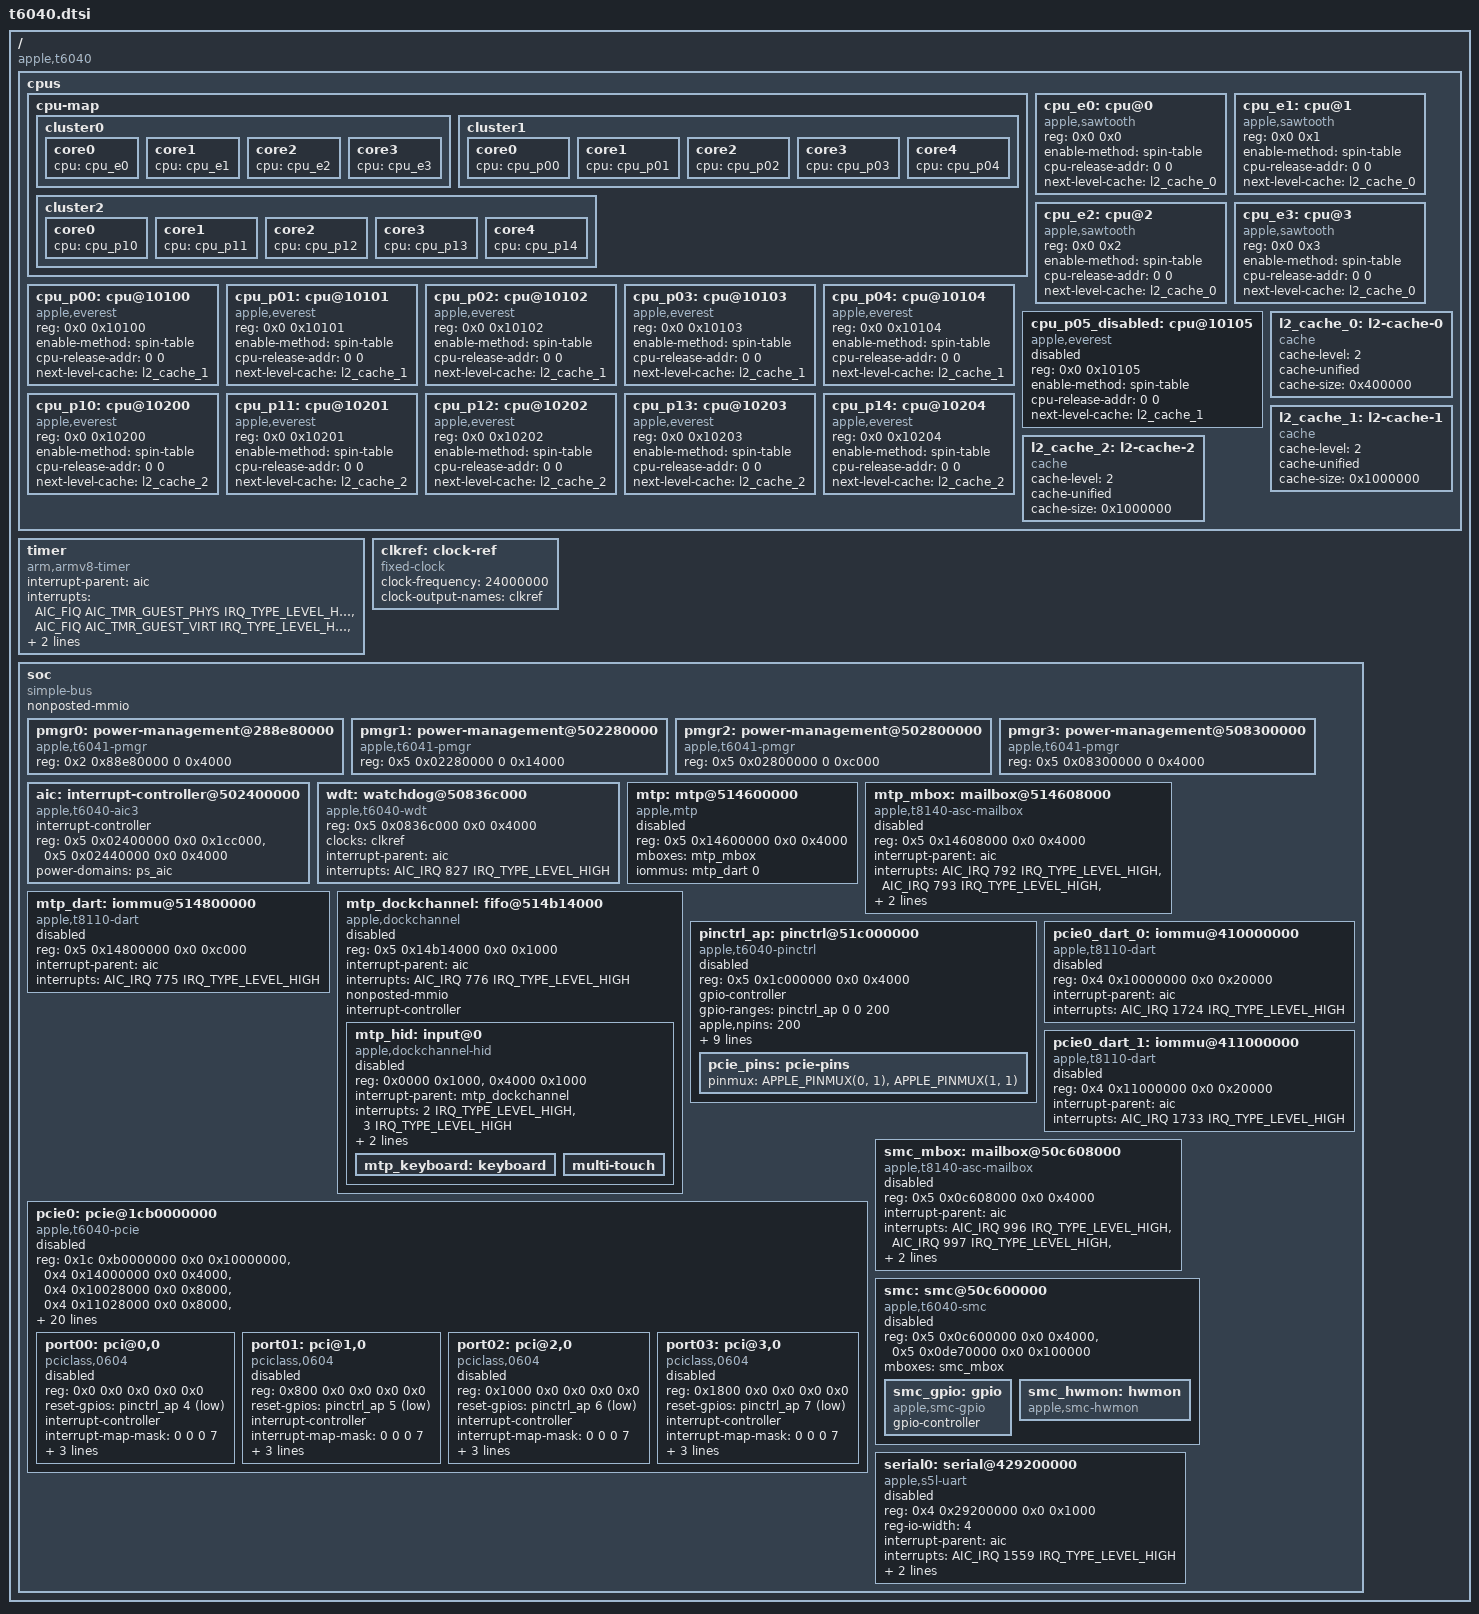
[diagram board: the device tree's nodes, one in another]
// SPDX-License-Identifier: GPL-2.0+ OR MIT
/*
 * Apple T6040 "M4 Pro" SoC
 *
 * The M4-generation Pro die: fills the gap between t8132 (M4) and t6050
 * (M5 Pro/Max). M4-generation IP (apple,sawtooth E / apple,everest P cores,
 * t8122-aic3) in a Pro-die multi-cluster layout (4E + 5P + 5P).
 *
 * All reg/irq values verified against the live j614s ADT (2026-07-10); see
 * m1n1 .plans/2026-07-10-t6040-kboot-fdt-plan.md and dts/README.md.
 *
 * Copyright The Asahi Linux Contributors
 */

#include <dt-bindings/gpio/gpio.h>
#include <dt-bindings/interrupt-controller/apple-aic.h>
#include <dt-bindings/interrupt-controller/irq.h>
#include <dt-bindings/pinctrl/apple.h>

/ {
	compatible = "apple,t6040", "apple,arm-platform";

	#address-cells = <2>;
	#size-cells = <2>;

	cpus {
		#address-cells = <2>;
		#size-cells = <0>;

		cpu-map {
			cluster0 {
				core0 {
					cpu = <&cpu_e0>;
				};
				core1 {
					cpu = <&cpu_e1>;
				};
				core2 {
					cpu = <&cpu_e2>;
				};
				core3 {
					cpu = <&cpu_e3>;
				};
			};

			cluster1 {
				core0 {
					cpu = <&cpu_p00>;
				};
				core1 {
					cpu = <&cpu_p01>;
				};
				core2 {
					cpu = <&cpu_p02>;
				};
				core3 {
					cpu = <&cpu_p03>;
				};
				core4 {
					cpu = <&cpu_p04>;
				};
			};

			cluster2 {
				core0 {
					cpu = <&cpu_p10>;
				};
				core1 {
					cpu = <&cpu_p11>;
				};
				core2 {
					cpu = <&cpu_p12>;
				};
				core3 {
					cpu = <&cpu_p13>;
				};
				core4 {
					cpu = <&cpu_p14>;
				};
			};
		};

		cpu_e0: cpu@0 {
			compatible = "apple,sawtooth";
			device_type = "cpu";
			reg = <0x0 0x0>;
			enable-method = "spin-table";
			cpu-release-addr = <0 0>;
			next-level-cache = <&l2_cache_0>;
		};

		cpu_e1: cpu@1 {
			compatible = "apple,sawtooth";
			device_type = "cpu";
			reg = <0x0 0x1>;
			enable-method = "spin-table";
			cpu-release-addr = <0 0>;
			next-level-cache = <&l2_cache_0>;
		};

		cpu_e2: cpu@2 {
			compatible = "apple,sawtooth";
			device_type = "cpu";
			reg = <0x0 0x2>;
			enable-method = "spin-table";
			cpu-release-addr = <0 0>;
			next-level-cache = <&l2_cache_0>;
		};

		cpu_e3: cpu@3 {
			compatible = "apple,sawtooth";
			device_type = "cpu";
			reg = <0x0 0x3>;
			enable-method = "spin-table";
			cpu-release-addr = <0 0>;
			next-level-cache = <&l2_cache_0>;
		};

		cpu_p00: cpu@10100 {
			compatible = "apple,everest";
			device_type = "cpu";
			reg = <0x0 0x10100>;
			enable-method = "spin-table";
			cpu-release-addr = <0 0>;
			next-level-cache = <&l2_cache_1>;
		};

		cpu_p01: cpu@10101 {
			compatible = "apple,everest";
			device_type = "cpu";
			reg = <0x0 0x10101>;
			enable-method = "spin-table";
			cpu-release-addr = <0 0>;
			next-level-cache = <&l2_cache_1>;
		};

		cpu_p02: cpu@10102 {
			compatible = "apple,everest";
			device_type = "cpu";
			reg = <0x0 0x10102>;
			enable-method = "spin-table";
			cpu-release-addr = <0 0>;
			next-level-cache = <&l2_cache_1>;
		};

		cpu_p03: cpu@10103 {
			compatible = "apple,everest";
			device_type = "cpu";
			reg = <0x0 0x10103>;
			enable-method = "spin-table";
			cpu-release-addr = <0 0>;
			next-level-cache = <&l2_cache_1>;
		};

		cpu_p04: cpu@10104 {
			compatible = "apple,everest";
			device_type = "cpu";
			reg = <0x0 0x10104>;
			enable-method = "spin-table";
			cpu-release-addr = <0 0>;
			next-level-cache = <&l2_cache_1>;
		};

		/*
		 * t6040 is a chopped t6041 (M4 Max): the full P-cluster0 has 6 cores
		 * (MPIDR 0x10100..0x10105) but the 6th is fused off here. m1n1 still
		 * enumerates it as smp_id 9 (Apple's non-contiguous ADT numbering) and
		 * expects a DT cpu node at that positional slot to prune — dt_set_cpus
		 * uses a positional counter, so without this the P-cl1 nodes shift by one
		 * and fail MPIDR matching. NOT in cpu-map (m1n1 nops the node but does not
		 * clean cpu-map references), so it never reaches Linux.
		 */
		cpu_p05_disabled: cpu@10105 {
			compatible = "apple,everest";
			device_type = "cpu";
			reg = <0x0 0x10105>;
			enable-method = "spin-table";
			cpu-release-addr = <0 0>;
			next-level-cache = <&l2_cache_1>;
			status = "disabled";
		};

		cpu_p10: cpu@10200 {
			compatible = "apple,everest";
			device_type = "cpu";
			reg = <0x0 0x10200>;
			enable-method = "spin-table";
			cpu-release-addr = <0 0>;
			next-level-cache = <&l2_cache_2>;
		};

		cpu_p11: cpu@10201 {
			compatible = "apple,everest";
			device_type = "cpu";
			reg = <0x0 0x10201>;
			enable-method = "spin-table";
			cpu-release-addr = <0 0>;
			next-level-cache = <&l2_cache_2>;
		};

		cpu_p12: cpu@10202 {
			compatible = "apple,everest";
			device_type = "cpu";
			reg = <0x0 0x10202>;
			enable-method = "spin-table";
			cpu-release-addr = <0 0>;
			next-level-cache = <&l2_cache_2>;
		};

		cpu_p13: cpu@10203 {
			compatible = "apple,everest";
			device_type = "cpu";
			reg = <0x0 0x10203>;
			enable-method = "spin-table";
			cpu-release-addr = <0 0>;
			next-level-cache = <&l2_cache_2>;
		};

		cpu_p14: cpu@10204 {
			compatible = "apple,everest";
			device_type = "cpu";
			reg = <0x0 0x10204>;
			enable-method = "spin-table";
			cpu-release-addr = <0 0>;
			next-level-cache = <&l2_cache_2>;
		};

		l2_cache_0: l2-cache-0 {
			compatible = "cache";
			cache-level = <2>;
			cache-unified;
			cache-size = <0x400000>;
		};

		l2_cache_1: l2-cache-1 {
			compatible = "cache";
			cache-level = <2>;
			cache-unified;
			cache-size = <0x1000000>;
		};

		l2_cache_2: l2-cache-2 {
			compatible = "cache";
			cache-level = <2>;
			cache-unified;
			cache-size = <0x1000000>;
		};
	};

	timer {
		compatible = "arm,armv8-timer";
		interrupt-parent = <&aic>;
		interrupt-names = "phys", "virt", "hyp-phys", "hyp-virt";
		interrupts = <AIC_FIQ AIC_TMR_GUEST_PHYS IRQ_TYPE_LEVEL_HIGH>,
			     <AIC_FIQ AIC_TMR_GUEST_VIRT IRQ_TYPE_LEVEL_HIGH>,
			     <AIC_FIQ AIC_TMR_HV_PHYS IRQ_TYPE_LEVEL_HIGH>,
			     <AIC_FIQ AIC_TMR_HV_VIRT IRQ_TYPE_LEVEL_HIGH>;
	};

	clkref: clock-ref {
		compatible = "fixed-clock";
		#clock-cells = <0>;
		clock-frequency = <24000000>;
		clock-output-names = "clkref";
	};

	soc: soc {
		compatible = "simple-bus";
		#address-cells = <2>;
		#size-cells = <2>;

		ranges;
		nonposted-mmio;

		/* pmgr nodes; child power-controllers added in t6040-pmgr.dtsi */
		pmgr0: power-management@288e80000 {
			compatible = "apple,t6041-pmgr", "apple,t8103-pmgr", "syscon", "simple-mfd";
			#address-cells = <1>;
			#size-cells = <1>;
			reg = <0x2 0x88e80000 0 0x4000>;
		};

		pmgr1: power-management@502280000 {
			compatible = "apple,t6041-pmgr", "apple,t8103-pmgr", "syscon", "simple-mfd";
			#address-cells = <1>;
			#size-cells = <1>;
			reg = <0x5 0x02280000 0 0x14000>;
		};

		pmgr2: power-management@502800000 {
			compatible = "apple,t6041-pmgr", "apple,t8103-pmgr", "syscon", "simple-mfd";
			#address-cells = <1>;
			#size-cells = <1>;
			reg = <0x5 0x02800000 0 0xc000>;
		};

		pmgr3: power-management@508300000 {
			compatible = "apple,t6041-pmgr", "apple,t8103-pmgr", "syscon", "simple-mfd";
			#address-cells = <1>;
			#size-cells = <1>;
			reg = <0x5 0x08300000 0 0x4000>;
		};

		aic: interrupt-controller@502400000 {
			compatible = "apple,t6040-aic3", "apple,t8122-aic3";
			#interrupt-cells = <3>;
			interrupt-controller;

			/*
			 * reg[0]: Main MMIO range
			 * reg[1]: CPU Event/IACK register page (Base + aic-iack-offset 0x40000)
			 */
			reg = <0x5 0x02400000 0x0 0x1cc000>,
			      <0x5 0x02440000 0x0 0x4000>;
			reg-names = "core", "event";
			power-domains = <&ps_aic>;
		};

		wdt: watchdog@50836c000 {
			compatible = "apple,t6040-wdt", "apple,t8103-wdt";
			reg = <0x5 0x0836c000 0x0 0x4000>;
			clocks = <&clkref>;
			interrupt-parent = <&aic>;
			interrupts = <AIC_IRQ 827 IRQ_TYPE_LEVEL_HIGH>;
		};

		/*
		 * MTP carries the internal keyboard and trackpad over DockChannel.
		 * All addresses and IRQs below are from the J614s ADT. Keep the
		 * complete path disabled in the SoC description; the board-level
		 * bring-up DT enables it as one deliberately gated unit.
		 */
		mtp: mtp@514600000 {
			compatible = "apple,mtp", "apple,rtk-helper-asc4";
			reg = <0x5 0x14600000 0x0 0x4000>;
			reg-names = "asc";
			mboxes = <&mtp_mbox>;
			iommus = <&mtp_dart 0>;
			#helper-cells = <0>;
			status = "disabled";
		};

		mtp_mbox: mailbox@514608000 {
			compatible = "apple,t8140-asc-mailbox", "apple,asc-mailbox-v4";
			reg = <0x5 0x14608000 0x0 0x4000>;
			interrupt-parent = <&aic>;
			/*
			 * The J614s ADT lists these as [793, 792, 795, 794],
			 * with not-empty first in each pair. Linux's binding is
			 * semantic empty/not-empty order, so map the physical lines
			 * to [792, 793, 794, 795]. Exact J614s testing found that
			 * keeping raw ADT order loses the MTP hello interrupt.
			 */
			interrupts = <AIC_IRQ 792 IRQ_TYPE_LEVEL_HIGH>,
				     <AIC_IRQ 793 IRQ_TYPE_LEVEL_HIGH>,
				     <AIC_IRQ 794 IRQ_TYPE_LEVEL_HIGH>,
				     <AIC_IRQ 795 IRQ_TYPE_LEVEL_HIGH>;
			interrupt-names = "send-empty", "send-not-empty",
					  "recv-empty", "recv-not-empty";
			#mbox-cells = <0>;
			status = "disabled";
		};

		mtp_dart: iommu@514800000 {
			compatible = "apple,t8110-dart";
			reg = <0x5 0x14800000 0x0 0xc000>;
			interrupt-parent = <&aic>;
			interrupts = <AIC_IRQ 775 IRQ_TYPE_LEVEL_HIGH>;
			#iommu-cells = <1>;
			status = "disabled";
		};

		mtp_dockchannel: fifo@514b14000 {
			compatible = "apple,dockchannel";
			reg = <0x5 0x14b14000 0x0 0x1000>;
			reg-names = "irq";
			interrupt-parent = <&aic>;
			interrupts = <AIC_IRQ 776 IRQ_TYPE_LEVEL_HIGH>;
			ranges = <0x0 0x5 0x14b30000 0x8000>;
			nonposted-mmio;
			#address-cells = <1>;
			#size-cells = <1>;
			interrupt-controller;
			#interrupt-cells = <2>;
			status = "disabled";

			mtp_hid: input@0 {
				compatible = "apple,dockchannel-hid";
				reg = <0x0000 0x1000>,
				      <0x4000 0x1000>;
				reg-names = "config", "data";
				interrupt-parent = <&mtp_dockchannel>;
				interrupts = <2 IRQ_TYPE_LEVEL_HIGH>,
					     <3 IRQ_TYPE_LEVEL_HIGH>;
				interrupt-names = "tx", "rx";
				apple,fifo-size = <0x800>;
				apple,helper-cpu = <&mtp>;
				status = "disabled";

				mtp_keyboard: keyboard {
				};

				multi-touch {
				};
			};
		};

		/*
		 * ADT /arm-io/gpio0: 200 pins and seven AIC interrupt groups.
		 * PCIe CLKREQ for populated ports 0/1 is GPIO 0/1, function 1.
		 * Keep the controller disabled until a board variant enables a
		 * PCIe endpoint path.
		 */
		pinctrl_ap: pinctrl@51c000000 {
			compatible = "apple,t6040-pinctrl", "apple,t8122-pinctrl",
				     "apple,t8103-pinctrl";
			reg = <0x5 0x1c000000 0x0 0x4000>;

			gpio-controller;
			#gpio-cells = <2>;
			gpio-ranges = <&pinctrl_ap 0 0 200>;
			apple,npins = <200>;

			interrupt-controller;
			#interrupt-cells = <2>;
			interrupt-parent = <&aic>;
			interrupts = <AIC_IRQ 478 IRQ_TYPE_LEVEL_HIGH>,
				     <AIC_IRQ 479 IRQ_TYPE_LEVEL_HIGH>,
				     <AIC_IRQ 480 IRQ_TYPE_LEVEL_HIGH>,
				     <AIC_IRQ 481 IRQ_TYPE_LEVEL_HIGH>,
				     <AIC_IRQ 482 IRQ_TYPE_LEVEL_HIGH>,
				     <AIC_IRQ 483 IRQ_TYPE_LEVEL_HIGH>,
				     <AIC_IRQ 484 IRQ_TYPE_LEVEL_HIGH>;
			status = "disabled";

			pcie_pins: pcie-pins {
				pinmux = <APPLE_PINMUX(0, 1)>,
					 <APPLE_PINMUX(1, 1)>;
			};
		};

		pcie0_dart_0: iommu@410000000 {
			compatible = "apple,t8110-dart";
			reg = <0x4 0x10000000 0x0 0x20000>;
			interrupt-parent = <&aic>;
			interrupts = <AIC_IRQ 1724 IRQ_TYPE_LEVEL_HIGH>;
			#iommu-cells = <1>;
			status = "disabled";
		};

		pcie0_dart_1: iommu@411000000 {
			compatible = "apple,t8110-dart";
			reg = <0x4 0x11000000 0x0 0x20000>;
			interrupt-parent = <&aic>;
			interrupts = <AIC_IRQ 1733 IRQ_TYPE_LEVEL_HIGH>;
			#iommu-cells = <1>;
			status = "disabled";
		};

		/*
		 * T6040 uses the T602x Linux-visible port layout. m1n1 owns
		 * shared PHY/clock initialization and leaves the complete ADT
		 * power-gate set active. Do not approximate the T6040
		 * APCIE_SYS_GP + APCIE_PHY_SW hierarchy with the binding's
		 * single power-domains entry.
		 */
		pcie0: pcie@1cb0000000 {
			compatible = "apple,t6040-pcie", "apple,t6020-pcie";
			device_type = "pci";

			reg = <0x1c 0xb0000000 0x0 0x10000000>,
			      <0x4 0x14000000 0x0 0x4000>,
			      <0x4 0x10028000 0x0 0x8000>,
			      <0x4 0x11028000 0x0 0x8000>,
			      <0x4 0x12028000 0x0 0x8000>,
			      <0x4 0x13028000 0x0 0x8000>,
			      <0x4 0x17020000 0x0 0x4000>,
			      <0x4 0x17024000 0x0 0x4000>,
			      <0x4 0x17028000 0x0 0x4000>,
			      <0x4 0x1702c000 0x0 0x4000>;
			reg-names = "config", "rc",
				    "port0", "port1", "port2", "port3",
				    "phy0", "phy1", "phy2", "phy3";

			interrupt-parent = <&aic>;
			interrupts = <AIC_IRQ 1723 IRQ_TYPE_LEVEL_HIGH>,
				     <AIC_IRQ 1732 IRQ_TYPE_LEVEL_HIGH>,
				     <AIC_IRQ 1741 IRQ_TYPE_LEVEL_HIGH>,
				     <AIC_IRQ 1750 IRQ_TYPE_LEVEL_HIGH>;

			msi-controller;
			msi-parent = <&pcie0>;
			msi-ranges = <&aic AIC_IRQ 2071 IRQ_TYPE_EDGE_RISING 32>;

			iommu-map = <0x100 &pcie0_dart_0 1 1>,
				    <0x200 &pcie0_dart_1 1 1>;
			iommu-map-mask = <0xff00>;

			bus-range = <0 8>;
			#address-cells = <3>;
			#size-cells = <2>;
			ranges = <0x43000000 0xb 0xc0000000
				  0xb 0xc0000000 0x0 0x20000000>,
				 <0x02000000 0x0 0x80000000
				  0xb 0x80000000 0x0 0x40000000>;

			pinctrl-0 = <&pcie_pins>;
			pinctrl-names = "default";
			status = "disabled";

			port00: pci@0,0 {
				compatible = "pciclass,0604";
				device_type = "pci";
				reg = <0x0 0x0 0x0 0x0 0x0>;
				reset-gpios = <&pinctrl_ap 4 GPIO_ACTIVE_LOW>;

				#address-cells = <3>;
				#size-cells = <2>;
				ranges;

				interrupt-controller;
				#interrupt-cells = <1>;
				interrupt-map-mask = <0 0 0 7>;
				interrupt-map = <0 0 0 1 &port00 0 0 0 0>,
						<0 0 0 2 &port00 0 0 0 1>,
						<0 0 0 3 &port00 0 0 0 2>,
						<0 0 0 4 &port00 0 0 0 3>;
				status = "disabled";
			};

			port01: pci@1,0 {
				compatible = "pciclass,0604";
				device_type = "pci";
				reg = <0x800 0x0 0x0 0x0 0x0>;
				reset-gpios = <&pinctrl_ap 5 GPIO_ACTIVE_LOW>;

				#address-cells = <3>;
				#size-cells = <2>;
				ranges;

				interrupt-controller;
				#interrupt-cells = <1>;
				interrupt-map-mask = <0 0 0 7>;
				interrupt-map = <0 0 0 1 &port01 0 0 0 0>,
						<0 0 0 2 &port01 0 0 0 1>,
						<0 0 0 3 &port01 0 0 0 2>,
						<0 0 0 4 &port01 0 0 0 3>;
				status = "disabled";
			};

			port02: pci@2,0 {
				compatible = "pciclass,0604";
				device_type = "pci";
				reg = <0x1000 0x0 0x0 0x0 0x0>;
				reset-gpios = <&pinctrl_ap 6 GPIO_ACTIVE_LOW>;

				#address-cells = <3>;
				#size-cells = <2>;
				ranges;

				interrupt-controller;
				#interrupt-cells = <1>;
				interrupt-map-mask = <0 0 0 7>;
				interrupt-map = <0 0 0 1 &port02 0 0 0 0>,
						<0 0 0 2 &port02 0 0 0 1>,
						<0 0 0 3 &port02 0 0 0 2>,
						<0 0 0 4 &port02 0 0 0 3>;
				status = "disabled";
			};

			port03: pci@3,0 {
				compatible = "pciclass,0604";
				device_type = "pci";
				reg = <0x1800 0x0 0x0 0x0 0x0>;
				reset-gpios = <&pinctrl_ap 7 GPIO_ACTIVE_LOW>;

				#address-cells = <3>;
				#size-cells = <2>;
				ranges;

				interrupt-controller;
				#interrupt-cells = <1>;
				interrupt-map-mask = <0 0 0 7>;
				interrupt-map = <0 0 0 1 &port03 0 0 0 0>,
						<0 0 0 2 &port03 0 0 0 1>,
						<0 0 0 3 &port03 0 0 0 2>,
						<0 0 0 4 &port03 0 0 0 3>;
				status = "disabled";
			};
		};

		/*
		 * The SMC MMIO/mailbox mapping comes from the J614s ADT. The
		 * SRAM base at 0x50de70000 is hardware-observed from RTKit
		 * buffer requests; the 1 MiB window size follows existing Apple
		 * SMC descriptions and has not been independently measured on
		 * T6040. Keep the path disabled until a board variant needs it.
		 */
		smc_mbox: mailbox@50c608000 {
			compatible = "apple,t8140-asc-mailbox", "apple,asc-mailbox-v4";
			reg = <0x5 0x0c608000 0x0 0x4000>;
			interrupt-parent = <&aic>;
			interrupts = <AIC_IRQ 996 IRQ_TYPE_LEVEL_HIGH>,
				     <AIC_IRQ 997 IRQ_TYPE_LEVEL_HIGH>,
				     <AIC_IRQ 998 IRQ_TYPE_LEVEL_HIGH>,
				     <AIC_IRQ 999 IRQ_TYPE_LEVEL_HIGH>;
			interrupt-names = "send-empty", "send-not-empty",
					  "recv-empty", "recv-not-empty";
			#mbox-cells = <0>;
			status = "disabled";
		};

		smc: smc@50c600000 {
			compatible = "apple,t6040-smc", "apple,t8103-smc";
			reg = <0x5 0x0c600000 0x0 0x4000>,
			      <0x5 0x0de70000 0x0 0x100000>;
			reg-names = "smc", "sram";
			mboxes = <&smc_mbox>;
			status = "disabled";

			smc_gpio: gpio {
				compatible = "apple,smc-gpio";
				gpio-controller;
				#gpio-cells = <2>;
			};

			smc_hwmon: hwmon {
				compatible = "apple,smc-hwmon";
			};
		};

		serial0: serial@429200000 {
			compatible = "apple,s5l-uart";
			reg = <0x4 0x29200000 0x0 0x1000>;
			reg-io-width = <4>;
			interrupt-parent = <&aic>;
			interrupts = <AIC_IRQ 1559 IRQ_TYPE_LEVEL_HIGH>;
			clocks = <&clkref>, <&clkref>;
			clock-names = "uart", "clk_uart_baud0";
			power-domains = <&ps_uart0>;
			status = "disabled";
		};
	};
};

#include "t6040-pmgr.dtsi"
